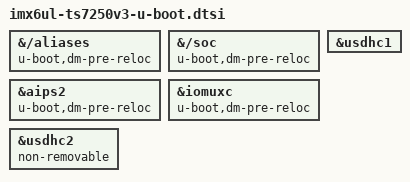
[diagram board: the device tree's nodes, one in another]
// SPDX-License-Identifier: GPL-2.0+
/*
 * Copyright 2020-2022 Technologic Systems, Inc. dba embeddedTS
 */

&{/aliases} {
	u-boot,dm-pre-reloc;
};

&{/soc} {
	u-boot,dm-pre-reloc;
};

&aips2 {
	u-boot,dm-pre-reloc;
};

&iomuxc {
	u-boot,dm-pre-reloc;
};

&usdhc1 {
	u-boot,dm-spl;
};

&usdhc2 {
	non-removable;
};
